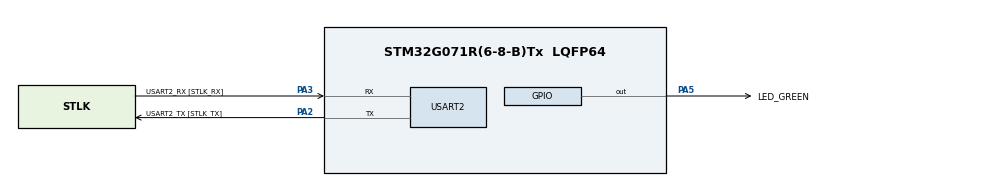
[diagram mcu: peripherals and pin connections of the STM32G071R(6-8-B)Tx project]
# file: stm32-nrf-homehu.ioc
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FREERTOS.Tasks01=defaultTask,24,128,StartDefaultTask,Default,NULL,Dynamic,NULL,NULL
Mcu.Family=STM32G0
Mcu.Name=STM32G071R(6-8-B)Tx
Mcu.Package=LQFP64
NVIC.TIM6_DAC_LPTIM1_IRQn=true\:3\:0\:false\:false\:true\:false\:false\:true\:true
NVIC.TimeBase=TIM6_DAC_LPTIM1_IRQn
NVIC.TimeBaseIP=TIM6
PA13.GPIO_Label=TMS
PA13.Mode=Serial_Wire
PA13.Signal=SYS_SWDIO
PA14-BOOT0.GPIO_Label=TCK
PA14-BOOT0.Mode=Serial_Wire
PA14-BOOT0.Signal=SYS_SWCLK
PA2.GPIO_Label=USART2_TX [STLK_TX]
PA2.GPIO_PuPd=GPIO_PULLUP
PA2.Mode=Asynchronous
PA2.Signal=USART2_TX
PA3.GPIO_Label=USART2_RX [STLK_RX]
PA3.GPIO_PuPd=GPIO_PULLUP
PA3.Mode=Asynchronous
PA3.Signal=USART2_RX
PA5.GPIO_Label=LED_GREEN
PA5.GPIO_Speed=GPIO_SPEED_FREQ_HIGH
PA5.Signal=GPIO_Output
PC13.Mode=SYS_WakeUp1
PC13.Signal=SYS_WKUP2
PC14-OSC32_IN\ (PC14).Mode=LSE-External-Oscillator
PC14-OSC32_IN\ (PC14).Signal=RCC_OSC32_IN
PC15-OSC32_OUT\ (PC15).Mode=LSE-External-Oscillator
PC15-OSC32_OUT\ (PC15).Signal=RCC_OSC32_OUT
PF0-OSC_IN\ (PF0).GPIO_Label=MCO
PF0-OSC_IN\ (PF0).Mode=HSE-External-Clock-Source
PF0-OSC_IN\ (PF0).Signal=RCC_OSC_IN
ProjectManager.HeapSize=0x200
ProjectManager.StackSize=0x400
ProjectManager.TargetToolchain=CMake
RCC.ADCFreq_Value=64000000
RCC.AHBFreq_Value=64000000
RCC.CortexFreq_Value=64000000
RCC.EXTERNAL_CLOCK_VALUE=12288000
RCC.HCLKFreq_Value=64000000
RCC.HSE_VALUE=8000000
RCC.HSI_VALUE=16000000
RCC.SYSCLKFreq_VALUE=64000000
RCC.SYSCLKSource=RCC_SYSCLKSOURCE_PLLCLK
RCC.VCOOutputFreq_Value=128000000
USART2.VirtualMode-Asynchronous=VM_ASYNC
VP_FREERTOS_VS_CMSIS_V2.Mode=CMSIS_V2
VP_SYS_VS_tim6.Mode=TIM6
board=NUCLEO-G071RB

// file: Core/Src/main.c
/* USER CODE BEGIN Header */
/**
  ******************************************************************************
  * @file           : main.c
  * @brief          : Main program body
  ******************************************************************************
  * @attention
  *
  * Copyright (c) 2026 STMicroelectronics.
  * All rights reserved.
  *
  * This software is licensed under terms that can be found in the LICENSE file
  * in the root directory of this software component.
  * If no LICENSE file comes with this software, it is provided AS-IS.
  *
  ******************************************************************************
  */
/* USER CODE END Header */
#include "main.h"
#include "FreeRTOS.h"
#include "cmsis_os.h"
#include "cmsis_os2.h"
#include "spi.h"
#include "stm32g071xx.h"
#include "stm32g0xx_ll_utils.h"
#include "usart.h"
#include "gpio.h"

/* USER CODE BEGIN Includes */
#include "systemConf.h"
#include "stm32g0xx_ll_bus.h"
#include "stm32g0xx_ll_gpio.h"
#include "stm32g0xx_ll_spi.h"
#include "nrf24l01.h"
#include <stdint.h>

/* USER CODE END Includes */

/* USER CODE BEGIN PV */
TaskHandle_t Task1 = NULL;
uint8_t data[5] = {0x12, 0x34, 0x56, 0x78, 0x90};
uint8_t result =0;
/* USER CODE END PV */

void SystemClock_Config(void);
void MX_FREERTOS_Init(void);

/* USER CODE BEGIN 0 */
void Task1Handler(void *params){
  while (1) {
    nrf24_Transmit(data, 5);
    do {
        result = nrf24_CheckTransmission();
    } while (result == 2);

    if (result == 1) {
        LL_GPIO_SetOutputPin(GPIOA, LL_GPIO_PIN_0);
        LL_GPIO_ResetOutputPin(GPIOA, LL_GPIO_PIN_1);
    } else {
        LL_GPIO_SetOutputPin(GPIOA, LL_GPIO_PIN_1);
        LL_GPIO_ResetOutputPin(GPIOA, LL_GPIO_PIN_0);
    }

    osDelay(1000);
  }
}
/* USER CODE END 0 */

int main(void)
{

  /* MCU Configuration--------------------------------------------------------*/

  /* Reset of all peripherals, Initializes the Flash interface and the Systick. */
  HAL_Init();

  /* Configure the system clock */
  SystemClock_Config();

  /* Initialize all configured peripherals */
  MX_GPIO_Init();
  MX_USART2_UART_Init();
 // MX_SPI1_Init();
  /* USER CODE BEGIN 2 */
  SystemConfig();

  /************************************ Configuration nrf ************************/
  nrf24_DefaultConfiguration();
  nrf24_AwakeForTx();
  LL_mDelay(2);

  /************************************  TASK CREATE  ****************************/
  xTaskCreate(Task1Handler, "Task1", 128, NULL, 2, &Task1);
  /* USER CODE END 2 */

  /* Init scheduler */
  osKernelInitialize();  /* Call init function for freertos objects (in cmsis_os2.c) */
  MX_FREERTOS_Init();

  /* Start scheduler */
  osKernelStart();

  /* We should never get here as control is now taken by the scheduler */

  /* Infinite loop */
  while (1)
  {

  }
}

void SystemClock_Config(void)
{
  LL_FLASH_SetLatency(LL_FLASH_LATENCY_2);
  while(LL_FLASH_GetLatency() != LL_FLASH_LATENCY_2)
  {
  }

  /* HSI configuration and activation */
  LL_RCC_HSI_Enable();
  while(LL_RCC_HSI_IsReady() != 1)
  {
  }

  /* Main PLL configuration and activation */
  LL_RCC_PLL_ConfigDomain_SYS(LL_RCC_PLLSOURCE_HSI, LL_RCC_PLLM_DIV_1, 8, LL_RCC_PLLR_DIV_2);
  LL_RCC_PLL_Enable();
  LL_RCC_PLL_EnableDomain_SYS();
  while(LL_RCC_PLL_IsReady() != 1)
  {
  }

  /* Set AHB prescaler*/
  LL_RCC_SetAHBPrescaler(LL_RCC_SYSCLK_DIV_1);

  /* Sysclk activation on the main PLL */
  LL_RCC_SetSysClkSource(LL_RCC_SYS_CLKSOURCE_PLL);
  while(LL_RCC_GetSysClkSource() != LL_RCC_SYS_CLKSOURCE_STATUS_PLL)
  {
  }

  /* Set APB1 prescaler*/
  LL_RCC_SetAPB1Prescaler(LL_RCC_APB1_DIV_1);
  /* Update CMSIS variable (which can be updated also through SystemCoreClockUpdate function) */
  LL_SetSystemCoreClock(64000000);

   /* Update the time base */
  if (HAL_InitTick (TICK_INT_PRIORITY) != HAL_OK)
  {
    Error_Handler();
  }
}

void HAL_TIM_PeriodElapsedCallback(TIM_HandleTypeDef *htim)
{
  if (htim->Instance == TIM6)
  {
    HAL_IncTick();
  }
}

void Error_Handler(void)
{
  __disable_irq();
  while (1)
  {
  }
}
